VERSION ""

NS_ :

BS_:

BU_: GCU TSMaster

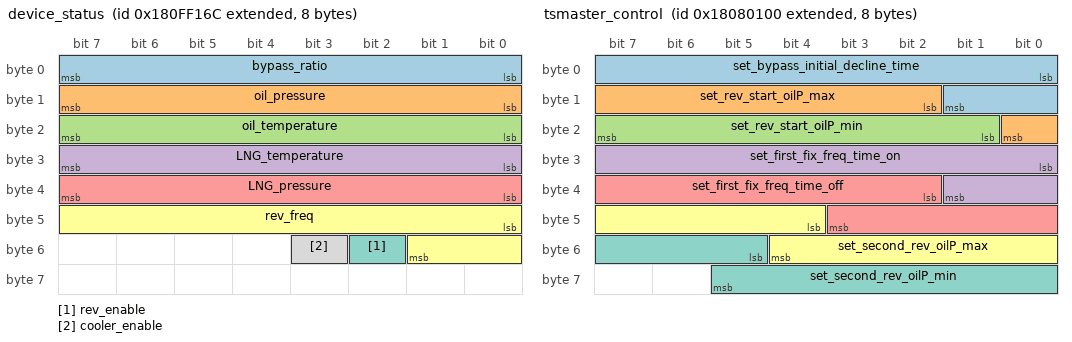
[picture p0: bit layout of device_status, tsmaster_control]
BO_ 2551181676 device_status: 8 GCU
 SG_ bypass_ratio : 0|8@1+ (0.2,0) [0|50] "%"  TSMaster
 SG_ oil_pressure : 8|8@1+ (0.15625,0) [0|40] "MPa"  TSMaster
 SG_ oil_temperature : 16|8@1+ (0.5098,-40) [-40|90] "C"  TSMaster
 SG_ LNG_temperature : 24|8@1+ (0.5098,-40) [-40|90] "C"  TSMaster
 SG_ LNG_pressure : 32|8@1+ (0.15625,0) [0|40] "MPa"  TSMaster
 SG_ rev_freq : 40|10@1+ (1,0) [0|1000] "min/次"  TSMaster
 SG_ rev_enable : 50|1@1+ (1,0) [0|1] ""  TSMaster
 SG_ cooler_enable : 51|1@1+ (1,0) [0|1] ""  TSMaster

BO_ 2550661376 tsmaster_control: 8 TSMaster
 SG_ set_bypass_initial_decline_time : 0|10@1+ (0.1,0) [0|100] "s"  GCU
 SG_ set_rev_start_oilP_max : 10|7@1+ (0.1,0) [0|10] "MPa"  GCU
 SG_ set_rev_start_oilP_min : 17|7@1+ (0.1,0) [0|10] "MPa"  GCU
 SG_ set_first_fix_freq_time_on : 24|10@1+ (0.1,0) [0|100] "s"  GCU
 SG_ set_first_fix_freq_time_off : 34|10@1+ (0.1,0) [0|100] "s"  GCU
 SG_ set_second_rev_oilP_max : 44|9@1+ (0.1,0) [0|40] "MPa"  GCU
 SG_ set_second_rev_oilP_min : 53|9@1+ (0.1,0) [0|40] "MPa"  GCU

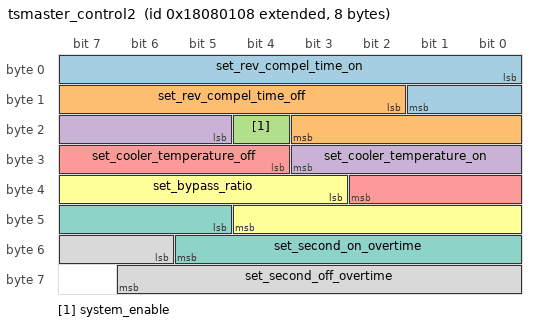
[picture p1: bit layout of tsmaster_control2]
BO_ 2550661384 tsmaster_control2: 8 TSMaster
 SG_ set_rev_compel_time_on : 0|10@1+ (0.1,0) [0|100] "s"  GCU
 SG_ set_rev_compel_time_off : 10|10@1+ (0.1,0) [0|100] "s"  GCU
 SG_ system_enable : 20|1@1+ (1,0) [0|1] ""  GCU
 SG_ set_cooler_temperature_on : 21|7@1+ (1,0) [0|100] "C"  GCU
 SG_ set_cooler_temperature_off : 28|7@1+ (1,0) [0|100] "C"  GCU
 SG_ set_bypass_ratio : 35|10@1+ (0.1,0) [0|50] "%"  GCU
 SG_ set_second_on_overtime : 45|9@1+ (0.1,0) [0|100] "s"  GCU
 SG_ set_second_off_overtime : 54|9@1+ (0.1,0) [0|100] "s"  GCU

CM_ SG_ 2551181676 bypass_ratio "旁通阀比例 (Bypass valve ratio)";
CM_ SG_ 2551181676 oil_pressure "油压 (Oil pressure)";
CM_ SG_ 2551181676 oil_temperature "油温 (Oil temperature)";
CM_ SG_ 2551181676 LNG_temperature "LNG温度 (LNG temperature)";
CM_ SG_ 2551181676 LNG_pressure "LNG压力 (LNG pressure)";
CM_ SG_ 2551181676 rev_freq "换向频率 (Reversal frequency)";
CM_ SG_ 2551181676 rev_enable "换向阀使能状态 (0关1开) (Reversal valve enable status)";
CM_ SG_ 2551181676 cooler_enable "风冷器使能状态 (0关1开) (Cooler enable status)";
CM_ SG_ 2550661376 set_bypass_initial_decline_time "设置旁通阀起始下降时间 (Set bypass valve initial decline time)";
CM_ SG_ 2550661376 set_rev_start_oilP_max "换向阀启动油压限制最大值设置 (Reversing valve start oil pressure limit maximum value setting)";
CM_ SG_ 2550661376 set_rev_start_oilP_min "换向阀启动油压限制最小值设置 (Reversing valve start oil pressure limit minimum value setting)";
CM_ SG_ 2550661376 set_first_fix_freq_time_on "第一阶段换向阀固定频率设置开启时常 (First stage reversing valve fixed frequency setting ON duration)";
CM_ SG_ 2550661376 set_first_fix_freq_time_off "第一阶段换向阀固定频率设置关闭时常 (First stage reversing valve fixed frequency setting OFF duration)";
CM_ SG_ 2550661376 set_second_rev_oilP_max "第二阶段换向的最大油压值设置 (Second stage reversing maximum oil pressure value setting)";
CM_ SG_ 2550661376 set_second_rev_oilP_min "第二阶段换向的最小油压值设置 (Second stage reversing minimum oil pressure value setting)";
CM_ SG_ 2550661384 set_rev_compel_time_on "第二阶段强制换向开启时间 (Second stage forced reversing ON time)";
CM_ SG_ 2550661384 set_rev_compel_time_off "第二阶段强制换向关闭时间 (Second stage forced reversing OFF time)";
CM_ SG_ 2550661384 system_enable "系统开关(0关1开) (System switch (0=OFF, 1=ON))";
CM_ SG_ 2550661384 set_cooler_temperature_on "设置风冷器开启温度 (Set cooler ON temperature)";
CM_ SG_ 2550661384 set_cooler_temperature_off "设置风冷器关闭温度 (Set cooler OFF temperature)";
CM_ SG_ 2550661384 set_bypass_ratio "设置旁通阀比例 (Set bypass valve ratio)";
CM_ SG_ 2550661384 set_second_on_overtime "第二阶段换向开启超时 (Second stage reversing ON overtime)";
CM_ SG_ 2550661384 set_second_off_overtime "第二阶段换向关闭超时 (Second stage reversing OFF overtime)";
BA_DEF_ BO_  "GenMsgCycleTime" INT 0 10000;
BA_DEF_ BO_  "GenMsgSendType" STRING ;
BA_DEF_DEF_  "GenMsgCycleTime" 0;
BA_DEF_DEF_  "GenMsgSendType" "";
BA_ "GenMsgCycleTime" BO_ 2551181676 10;
BA_ "GenMsgSendType" BO_ 2551181676 "Cyclic";
BA_ "GenMsgCycleTime" BO_ 2550661376 100;
BA_ "GenMsgSendType" BO_ 2550661376 "IfActive";
BA_ "GenMsgCycleTime" BO_ 2550661384 100;
BA_ "GenMsgSendType" BO_ 2550661384 "IfActive";
VAL_ 2551181676 rev_enable 0 "OFF" 1 "ON" ;
VAL_ 2551181676 cooler_enable 0 "OFF" 1 "ON" ;
VAL_ 2550661384 system_enable 0 "Disable" 1 "Enable" ;
